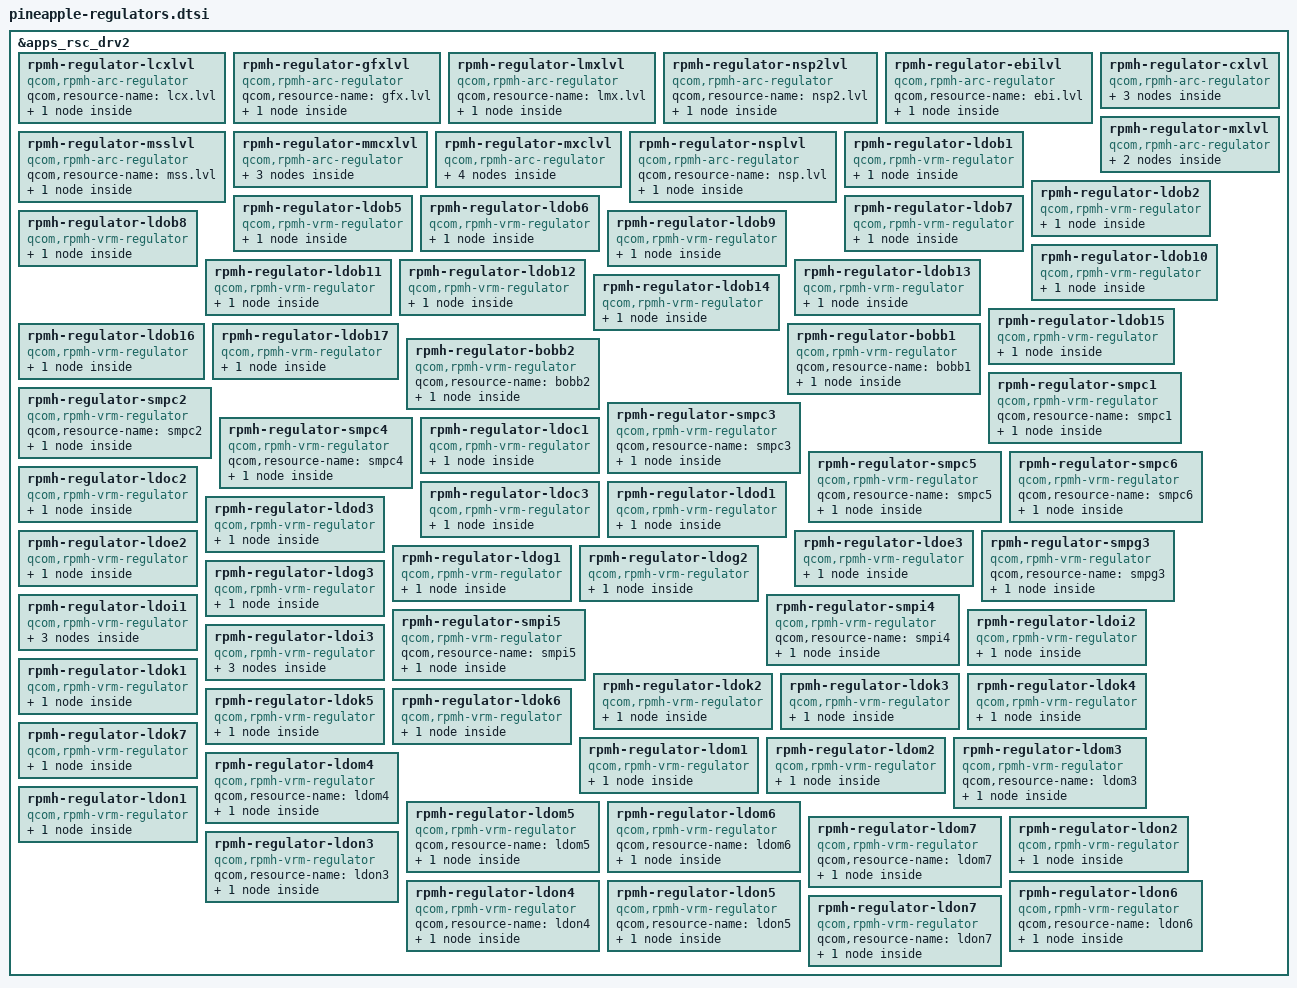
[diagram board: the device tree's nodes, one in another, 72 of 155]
// SPDX-License-Identifier: BSD-3-Clause
/*
 * Copyright (c) 2022-2023 Qualcomm Innovation Center, Inc. All rights reserved.
 */

#include <dt-bindings/regulator/qcom,rpmh-regulator-levels.h>

&apps_rsc_drv2 {
	rpmh-regulator-lcxlvl {
		compatible = "qcom,rpmh-arc-regulator";
		qcom,resource-name = "lcx.lvl";

		VDD_LPI_CX_LEVEL: S4D_LEVEL:
		pm_v6d_s4_level: regulator-pm-v6d-s4-level {
			regulator-name = "pm_v6d_s4_level";
			qcom,set = <RPMH_REGULATOR_SET_ALL>;
			regulator-min-microvolt =
				<RPMH_REGULATOR_LEVEL_RETENTION>;
			regulator-max-microvolt =
				<RPMH_REGULATOR_LEVEL_MAX>;
			qcom,init-voltage-level =
				<RPMH_REGULATOR_LEVEL_RETENTION>;
		};
	};

	rpmh-regulator-gfxlvl {
		compatible = "qcom,rpmh-arc-regulator";
		qcom,resource-name = "gfx.lvl";

		VDD_GFX_LEVEL: S5D_LEVEL:
		pm_v6d_s5_level: regulator-pm-v6d-s5-level {
			regulator-name = "pm_v6d_s5_level";
			qcom,set = <RPMH_REGULATOR_SET_ALL>;
			regulator-min-microvolt =
				<RPMH_REGULATOR_LEVEL_RETENTION>;
			regulator-max-microvolt =
				<RPMH_REGULATOR_LEVEL_MAX>;
			qcom,init-voltage-level =
				<RPMH_REGULATOR_LEVEL_RETENTION>;
		};
	};

	rpmh-regulator-lmxlvl {
		compatible = "qcom,rpmh-arc-regulator";
		qcom,resource-name = "lmx.lvl";

		VDD_LPI_MX_LEVEL: L2D_LEVEL:
		pm_v6d_l2_level: regulator-pm-v6d-l2-level {
			regulator-name = "pm_v6d_l2_level";
			qcom,set = <RPMH_REGULATOR_SET_ALL>;
			regulator-min-microvolt =
				<RPMH_REGULATOR_LEVEL_RETENTION>;
			regulator-max-microvolt =
				<RPMH_REGULATOR_LEVEL_MAX>;
			qcom,init-voltage-level =
				<RPMH_REGULATOR_LEVEL_RETENTION>;
		};
	};

	rpmh-regulator-nsp2lvl {
		compatible = "qcom,rpmh-arc-regulator";
		qcom,resource-name = "nsp2.lvl";

		VDD_NSP2_LEVEL: S1G_LEVEL:
		pm_v6g_s1_level: regulator-pm-v6g-s1-level {
			regulator-name = "pm_v6g_s1_level";
			qcom,set = <RPMH_REGULATOR_SET_ALL>;
			regulator-min-microvolt =
				<RPMH_REGULATOR_LEVEL_RETENTION>;
			regulator-max-microvolt =
				<RPMH_REGULATOR_LEVEL_MAX>;
			qcom,init-voltage-level =
				<RPMH_REGULATOR_LEVEL_RETENTION>;
		};
	};

	rpmh-regulator-ebilvl {
		compatible = "qcom,rpmh-arc-regulator";
		qcom,resource-name = "ebi.lvl";

		VDD_EBI_LEVEL: S4G_LEVEL:
		pm_v6g_s4_level: regulator-pm-v6g-s4-level {
			regulator-name = "pm_v6g_s4_level";
			qcom,set = <RPMH_REGULATOR_SET_ALL>;
			regulator-min-microvolt =
				<RPMH_REGULATOR_LEVEL_RETENTION>;
			regulator-max-microvolt =
				<RPMH_REGULATOR_LEVEL_MAX>;
			qcom,init-voltage-level =
				<RPMH_REGULATOR_LEVEL_RETENTION>;
		};
	};

	rpmh-regulator-msslvl {
		compatible = "qcom,rpmh-arc-regulator";
		qcom,resource-name = "mss.lvl";

		VDD_MODEM_LEVEL: S5G_LEVEL:
		pm_v6g_s5_level: regulator-pm-v6g-s5-level {
			regulator-name = "pm_v6g_s5_level";
			qcom,set = <RPMH_REGULATOR_SET_ALL>;
			regulator-min-microvolt =
				<RPMH_REGULATOR_LEVEL_RETENTION>;
			regulator-max-microvolt =
				<RPMH_REGULATOR_LEVEL_MAX>;
			qcom,init-voltage-level =
				<RPMH_REGULATOR_LEVEL_RETENTION>;
		};
	};

	rpmh-regulator-cxlvl {
		compatible = "qcom,rpmh-arc-regulator";
		qcom,resource-name = "cx.lvl";
		proxy-supply = <&VDD_CX_LEVEL>;

		VDD_CX_LEVEL: S8I_LEVEL:
		pm_v8_s8_level: regulator-pm-v8-s8-level {
			regulator-name = "pm_v8_s8_level";
			qcom,set = <RPMH_REGULATOR_SET_ALL>;
			regulator-min-microvolt =
				<RPMH_REGULATOR_LEVEL_RETENTION>;
			regulator-max-microvolt =
				<RPMH_REGULATOR_LEVEL_MAX>;
			qcom,init-voltage-level =
				<RPMH_REGULATOR_LEVEL_TURBO>;
			qcom,proxy-consumer-enable;
			qcom,proxy-consumer-voltage =
				<RPMH_REGULATOR_LEVEL_TURBO
				 RPMH_REGULATOR_LEVEL_MAX>;
		};

		VDD_CX_LEVEL_AO: S8I_LEVEL_AO:
		pm_v8_s8_level_ao: regulator-pm-v8-s8-level-ao {
			regulator-name = "pm_v8_s8_level_ao";
			qcom,set = <RPMH_REGULATOR_SET_ACTIVE>;
			regulator-min-microvolt =
				<RPMH_REGULATOR_LEVEL_RETENTION>;
			regulator-max-microvolt =
				<RPMH_REGULATOR_LEVEL_MAX>;
			qcom,init-voltage-level =
				<RPMH_REGULATOR_LEVEL_RETENTION>;
		};

		VDD_CX_MMCX_SUPPLY_LEVEL: regulator-pm-v8-s8-mmcx-sup-level {
			regulator-name = "pm_v8_s8_mmcx_sup_level";
			qcom,set = <RPMH_REGULATOR_SET_ALL>;
			regulator-min-microvolt =
				<RPMH_REGULATOR_LEVEL_MIN_SVS>;
			regulator-max-microvolt =
				<RPMH_REGULATOR_LEVEL_MAX>;
			qcom,init-voltage-level =
				<RPMH_REGULATOR_LEVEL_MIN_SVS>;
		};
	};

	rpmh-regulator-mmcxlvl {
		compatible = "qcom,rpmh-arc-regulator";
		qcom,resource-name = "mmcx.lvl";
		proxy-supply = <&VDD_MMCX_LEVEL>;

		VDD_MMCX_LEVEL: VDD_MM_LEVEL: S1I_LEVEL:
		pm_v8_s1_level: regulator-pm-v8-s1-level {
			regulator-name = "pm_v8_s1_level";
			qcom,set = <RPMH_REGULATOR_SET_ALL>;
			pm_v8_s1_level-parent-supply =
				<&VDD_CX_MMCX_SUPPLY_LEVEL>;
			regulator-min-microvolt =
				<RPMH_REGULATOR_LEVEL_LOW_SVS_D1>;
			regulator-max-microvolt =
				<RPMH_REGULATOR_LEVEL_MAX>;
			qcom,init-voltage-level =
				<RPMH_REGULATOR_LEVEL_TURBO>;
			qcom,proxy-consumer-enable;
			qcom,proxy-consumer-voltage =
				<RPMH_REGULATOR_LEVEL_TURBO
				 RPMH_REGULATOR_LEVEL_MAX>;
		};

		VDD_MMCX_LEVEL_AO: VDD_MM_LEVEL_AO: S1I_LEVEL_AO:
		pm_v8_s1_level_ao: regulator-pm-v8-s1-level-ao {
			regulator-name = "pm_v8_s1_level_ao";
			qcom,set = <RPMH_REGULATOR_SET_ACTIVE>;
			regulator-min-microvolt =
				<RPMH_REGULATOR_LEVEL_LOW_SVS_D1>;
			regulator-max-microvolt =
				<RPMH_REGULATOR_LEVEL_MAX>;
			qcom,init-voltage-level =
				<RPMH_REGULATOR_LEVEL_LOW_SVS_D1>;
		};

		regulator-pm-v8-s1-level-so {
			regulator-name = "pm_v8_s1_level_so";
			qcom,set = <RPMH_REGULATOR_SET_SLEEP>;
			regulator-min-microvolt =
				<RPMH_REGULATOR_LEVEL_LOW_SVS_D1>;
			regulator-max-microvolt =
				<RPMH_REGULATOR_LEVEL_MAX>;
			qcom,init-voltage-level =
				<RPMH_REGULATOR_LEVEL_LOW_SVS_D1>;
		};
	};

	rpmh-regulator-mxlvl {
		compatible = "qcom,rpmh-arc-regulator";
		qcom,resource-name = "mx.lvl";
		proxy-supply = <&VDD_MXA_LEVEL>;

		VDD_MXA_LEVEL: S3I_LEVEL:
		pm_v8_s3_level: regulator-pm-v8-s3-level {
			regulator-name = "pm_v8_s3_level";
			qcom,set = <RPMH_REGULATOR_SET_ALL>;
			regulator-min-microvolt =
				<RPMH_REGULATOR_LEVEL_RETENTION>;
			regulator-max-microvolt =
				<RPMH_REGULATOR_LEVEL_MAX>;
			qcom,init-voltage-level =
				<RPMH_REGULATOR_LEVEL_TURBO>;
			qcom,proxy-consumer-enable;
			qcom,proxy-consumer-voltage =
				<RPMH_REGULATOR_LEVEL_TURBO
				 RPMH_REGULATOR_LEVEL_MAX>;
		};

		VDD_MXA_LEVEL_AO: S3I_LEVEL_AO:
		pm_v8_s3_level_ao: regulator-pm-v8-s3-level-ao {
			regulator-name = "pm_v8_s3_level_ao";
			qcom,set = <RPMH_REGULATOR_SET_ACTIVE>;
			regulator-min-microvolt =
				<RPMH_REGULATOR_LEVEL_RETENTION>;
			regulator-max-microvolt =
				<RPMH_REGULATOR_LEVEL_MAX>;
			qcom,init-voltage-level =
				<RPMH_REGULATOR_LEVEL_RETENTION>;
		};
	};

	rpmh-regulator-mxclvl {
		compatible = "qcom,rpmh-arc-regulator";
		qcom,resource-name = "mxc.lvl";
		proxy-supply = <&VDD_MXC_LEVEL>;

		VDD_MXC_LEVEL: S3D_LEVEL:
		pm_v6d_s3_level: regulator-pm-v6d-s3-level {
			regulator-name = "pm_v6d_s3_level";
			qcom,set = <RPMH_REGULATOR_SET_ALL>;
			regulator-min-microvolt =
				<RPMH_REGULATOR_LEVEL_RETENTION>;
			regulator-max-microvolt =
				<RPMH_REGULATOR_LEVEL_MAX>;
			qcom,init-voltage-level =
				<RPMH_REGULATOR_LEVEL_TURBO>;
			qcom,proxy-consumer-enable;
			qcom,proxy-consumer-voltage =
				<RPMH_REGULATOR_LEVEL_TURBO
				 RPMH_REGULATOR_LEVEL_MAX>;
		};

		VDD_MXC_LEVEL_AO: S3D_LEVEL_AO:
		pm_v6d_s3_level_ao: regulator-pm-v6d-s3-level-ao {
			regulator-name = "pm_v6d_s3_level_ao";
			qcom,set = <RPMH_REGULATOR_SET_ACTIVE>;
			regulator-min-microvolt =
				<RPMH_REGULATOR_LEVEL_RETENTION>;
			regulator-max-microvolt =
				<RPMH_REGULATOR_LEVEL_MAX>;
			qcom,init-voltage-level =
				<RPMH_REGULATOR_LEVEL_RETENTION>;
		};

		VDD_MXC_MMCX_VOTER_LEVEL: VDD_MXC_MM_VOTER_LEVEL:
		VDD_MM_MXC_VOTER_LEVEL:
		regulator-pm-v6d-s3-mmcx-voter-level {
			regulator-name = "pm_v6d_s3_mmcx_voter_level";
			pm_v6d_s3_mmcx_voter_level-parent-supply =
				<&VDD_MMCX_LEVEL>;
			qcom,set = <RPMH_REGULATOR_SET_ALL>;
			regulator-min-microvolt =
				<RPMH_REGULATOR_LEVEL_MIN_SVS>;
			regulator-max-microvolt =
				<RPMH_REGULATOR_LEVEL_MAX>;
			qcom,init-voltage-level =
				<RPMH_REGULATOR_LEVEL_MIN_SVS>;
		};

		VDD_MXC_GFX_VOTER_LEVEL: VDD_GFX_MXC_VOTER_LEVEL:
		regulator-pm-v6d-s3-gfx-voter-level {
			regulator-name = "pm_v6d_s3_gfx_voter_level";
			pm_v6d_s3_gfx_voter_level-parent-supply =
				<&VDD_GFX_LEVEL>;
			qcom,set = <RPMH_REGULATOR_SET_ALL>;
			regulator-min-microvolt =
				<RPMH_REGULATOR_LEVEL_MIN_SVS>;
			regulator-max-microvolt =
				<RPMH_REGULATOR_LEVEL_MAX>;
			qcom,init-voltage-level =
				<RPMH_REGULATOR_LEVEL_MIN_SVS>;
		};
	};

	rpmh-regulator-nsplvl {
		compatible = "qcom,rpmh-arc-regulator";
		qcom,resource-name = "nsp.lvl";

		VDD_NSP1_LEVEL: S6I_LEVEL:
		pm_v8_s6_level: regulator-pm-v8-s6-level {
			regulator-name = "pm_v8_s6_level";
			qcom,set = <RPMH_REGULATOR_SET_ALL>;
			regulator-min-microvolt =
				<RPMH_REGULATOR_LEVEL_RETENTION>;
			regulator-max-microvolt =
				<RPMH_REGULATOR_LEVEL_MAX>;
			qcom,init-voltage-level =
				<RPMH_REGULATOR_LEVEL_RETENTION>;
		};
	};

	rpmh-regulator-ldob1 {
		compatible = "qcom,rpmh-vrm-regulator";
		qcom,resource-name = "ldob1";
		qcom,regulator-type = "pmic5-ldo";
		qcom,supported-modes =
			<RPMH_REGULATOR_MODE_LPM
			 RPMH_REGULATOR_MODE_HPM>;
		qcom,mode-threshold-currents = <0 30000>;

		L1B: pm_humu_l1: regulator-pm-humu-l1 {
			regulator-name = "pm_humu_l1";
			qcom,set = <RPMH_REGULATOR_SET_ALL>;
			regulator-min-microvolt = <1800000>;
			regulator-max-microvolt = <1800000>;
			qcom,init-voltage = <1800000>;
			qcom,init-mode = <RPMH_REGULATOR_MODE_HPM>;
		};
	};

	rpmh-regulator-ldob2 {
		compatible = "qcom,rpmh-vrm-regulator";
		qcom,resource-name = "ldob2";
		qcom,regulator-type = "pmic5-ldo";
		qcom,supported-modes =
			<RPMH_REGULATOR_MODE_LPM
			 RPMH_REGULATOR_MODE_HPM>;
		qcom,mode-threshold-currents = <0 10000>;

		L2B: pm_humu_l2: regulator-pm-humu-l2 {
			regulator-name = "pm_humu_l2";
			qcom,set = <RPMH_REGULATOR_SET_ALL>;
			regulator-min-microvolt = <3008000>;
			regulator-max-microvolt = <3008000>;
			qcom,init-voltage = <3008000>;
			qcom,init-mode = <RPMH_REGULATOR_MODE_HPM>;
		};
	};

	rpmh-regulator-ldob5 {
		compatible = "qcom,rpmh-vrm-regulator";
		qcom,resource-name = "ldob5";
		qcom,regulator-type = "pmic5-ldo";
		qcom,supported-modes =
			<RPMH_REGULATOR_MODE_LPM
			 RPMH_REGULATOR_MODE_HPM>;
		qcom,mode-threshold-currents = <0 10000>;

		L5B: pm_humu_l5: regulator-pm-humu-l5 {
			regulator-name = "pm_humu_l5";
			qcom,set = <RPMH_REGULATOR_SET_ALL>;
			regulator-min-microvolt = <3104000>;
			regulator-max-microvolt = <3104000>;
			qcom,init-voltage = <3104000>;
			qcom,init-mode = <RPMH_REGULATOR_MODE_HPM>;
		};
	};

	rpmh-regulator-ldob6 {
		compatible = "qcom,rpmh-vrm-regulator";
		qcom,resource-name = "ldob6";
		qcom,regulator-type = "pmic5-ldo";
		qcom,supported-modes =
			<RPMH_REGULATOR_MODE_LPM
			 RPMH_REGULATOR_MODE_HPM>;
		qcom,mode-threshold-currents = <0 10000>;

		L6B: pm_humu_l6: regulator-pm-humu-l6 {
			regulator-name = "pm_humu_l6";
			qcom,set = <RPMH_REGULATOR_SET_ALL>;
			regulator-min-microvolt = <1800000>;
			regulator-max-microvolt = <3008000>;
			qcom,init-voltage = <1800000>;
			qcom,init-mode = <RPMH_REGULATOR_MODE_HPM>;
		};
	};

	rpmh-regulator-ldob7 {
		compatible = "qcom,rpmh-vrm-regulator";
		qcom,resource-name = "ldob7";
		qcom,regulator-type = "pmic5-ldo";
		qcom,supported-modes =
			<RPMH_REGULATOR_MODE_LPM
			 RPMH_REGULATOR_MODE_HPM>;
		qcom,mode-threshold-currents = <0 10000>;

		L7B: pm_humu_l7: regulator-pm-humu-l7 {
			regulator-name = "pm_humu_l7";
			qcom,set = <RPMH_REGULATOR_SET_ALL>;
			regulator-min-microvolt = <1800000>;
			regulator-max-microvolt = <3008000>;
			qcom,init-voltage = <1800000>;
			qcom,init-mode = <RPMH_REGULATOR_MODE_HPM>;
		};
	};

	rpmh-regulator-ldob8 {
		compatible = "qcom,rpmh-vrm-regulator";
		qcom,resource-name = "ldob8";
		qcom,regulator-type = "pmic5-ldo";
		qcom,supported-modes =
			<RPMH_REGULATOR_MODE_LPM
			 RPMH_REGULATOR_MODE_HPM>;
		qcom,mode-threshold-currents = <0 10000>;

		L8B: pm_humu_l8: regulator-pm-humu-l8 {
			regulator-name = "pm_humu_l8";
			qcom,set = <RPMH_REGULATOR_SET_ALL>;
			regulator-min-microvolt = <1800000>;
			regulator-max-microvolt = <3008000>;
			qcom,init-voltage = <1800000>;
			qcom,init-mode = <RPMH_REGULATOR_MODE_HPM>;
		};
	};

	rpmh-regulator-ldob9 {
		compatible = "qcom,rpmh-vrm-regulator";
		qcom,resource-name = "ldob9";
		qcom,regulator-type = "pmic5-ldo";
		qcom,supported-modes =
			<RPMH_REGULATOR_MODE_LPM
			 RPMH_REGULATOR_MODE_HPM>;
		qcom,mode-threshold-currents = <0 10000>;

		L9B: pm_humu_l9: regulator-pm-humu-l9 {
			regulator-name = "pm_humu_l9";
			qcom,set = <RPMH_REGULATOR_SET_ALL>;
			regulator-min-microvolt = <2960000>;
			regulator-max-microvolt = <3008000>;
			qcom,init-voltage = <2960000>;
			qcom,init-mode = <RPMH_REGULATOR_MODE_HPM>;
		};
	};

	rpmh-regulator-ldob10 {
		compatible = "qcom,rpmh-vrm-regulator";
		qcom,resource-name = "ldob10";
		qcom,regulator-type = "pmic5-ldo";
		qcom,supported-modes =
			<RPMH_REGULATOR_MODE_LPM
			 RPMH_REGULATOR_MODE_HPM>;
		qcom,mode-threshold-currents = <0 30000>;

		L10B: pm_humu_l10: regulator-pm-humu-l10 {
			regulator-name = "pm_humu_l10";
			qcom,set = <RPMH_REGULATOR_SET_ALL>;
			regulator-min-microvolt = <1800000>;
			regulator-max-microvolt = <1800000>;
			qcom,init-voltage = <1800000>;
			qcom,init-mode = <RPMH_REGULATOR_MODE_HPM>;
		};
	};

	rpmh-regulator-ldob11 {
		compatible = "qcom,rpmh-vrm-regulator";
		qcom,resource-name = "ldob11";
		qcom,regulator-type = "pmic5-ldo";
		qcom,supported-modes =
			<RPMH_REGULATOR_MODE_LPM
			 RPMH_REGULATOR_MODE_HPM>;
		qcom,mode-threshold-currents = <0 30000>;
		proxy-supply = <&L11B>;

		L11B: pm_humu_l11: regulator-pm-humu-l11 {
			regulator-name = "pm_humu_l11";
			qcom,set = <RPMH_REGULATOR_SET_ALL>;
			regulator-min-microvolt = <1200000>;
			regulator-max-microvolt = <1200000>;
			qcom,init-voltage = <1200000>;
			qcom,init-mode = <RPMH_REGULATOR_MODE_HPM>;
			qcom,proxy-consumer-enable;
		};
	};

	rpmh-regulator-ldob12 {
		compatible = "qcom,rpmh-vrm-regulator";
		qcom,resource-name = "ldob12";
		qcom,regulator-type = "pmic5-ldo";
		qcom,supported-modes =
			<RPMH_REGULATOR_MODE_LPM
			 RPMH_REGULATOR_MODE_HPM>;
		qcom,mode-threshold-currents = <0 30000>;
		proxy-supply = <&L12B>;

		L12B: pm_humu_l12: regulator-pm-humu-l12 {
			regulator-name = "pm_humu_l12";
			qcom,set = <RPMH_REGULATOR_SET_ALL>;
			regulator-min-microvolt = <1800000>;
			regulator-max-microvolt = <1800000>;
			qcom,init-voltage = <1800000>;
			qcom,init-mode = <RPMH_REGULATOR_MODE_HPM>;
			qcom,proxy-consumer-enable;
		};
	};

	rpmh-regulator-ldob13 {
		compatible = "qcom,rpmh-vrm-regulator";
		qcom,resource-name = "ldob13";
		qcom,regulator-type = "pmic5-ldo";
		qcom,supported-modes =
			<RPMH_REGULATOR_MODE_LPM
			 RPMH_REGULATOR_MODE_HPM>;
		qcom,mode-threshold-currents = <0 10000>;
		proxy-supply = <&L13B>;

		L13B: pm_humu_l13: regulator-pm-humu-l13 {
			regulator-name = "pm_humu_l13";
			qcom,set = <RPMH_REGULATOR_SET_ALL>;
			regulator-min-microvolt = <3000000>;
			regulator-max-microvolt = <3000000>;
			qcom,init-voltage = <3000000>;
			qcom,init-mode = <RPMH_REGULATOR_MODE_HPM>;
			qcom,proxy-consumer-enable;
		};
	};

	rpmh-regulator-ldob14 {
		compatible = "qcom,rpmh-vrm-regulator";
		qcom,resource-name = "ldob14";
		qcom,regulator-type = "pmic5-ldo";
		qcom,supported-modes =
			<RPMH_REGULATOR_MODE_LPM
			 RPMH_REGULATOR_MODE_HPM>;
		qcom,mode-threshold-currents = <0 10000>;

		L14B: pm_humu_l14: regulator-pm-humu-l14 {
			regulator-name = "pm_humu_l14";
			qcom,set = <RPMH_REGULATOR_SET_ALL>;
			regulator-min-microvolt = <3200000>;
			regulator-max-microvolt = <3200000>;
			qcom,init-voltage = <3200000>;
			qcom,init-mode = <RPMH_REGULATOR_MODE_HPM>;
		};
	};

	rpmh-regulator-ldob15 {
		compatible = "qcom,rpmh-vrm-regulator";
		qcom,resource-name = "ldob15";
		qcom,regulator-type = "pmic5-ldo";
		qcom,supported-modes =
			<RPMH_REGULATOR_MODE_LPM
			 RPMH_REGULATOR_MODE_HPM>;
		qcom,mode-threshold-currents = <0 30000>;

		L15B: pm_humu_l15: regulator-pm-humu-l15 {
			regulator-name = "pm_humu_l15";
			qcom,set = <RPMH_REGULATOR_SET_ALL>;
			regulator-min-microvolt = <1800000>;
			regulator-max-microvolt = <1800000>;
			qcom,init-voltage = <1800000>;
			qcom,init-mode = <RPMH_REGULATOR_MODE_HPM>;
		};
	};

	rpmh-regulator-ldob16 {
		compatible = "qcom,rpmh-vrm-regulator";
		qcom,resource-name = "ldob16";
		qcom,regulator-type = "pmic5-ldo";
		qcom,supported-modes =
			<RPMH_REGULATOR_MODE_LPM
			 RPMH_REGULATOR_MODE_HPM>;
		qcom,mode-threshold-currents = <0 10000>;

		L16B: pm_humu_l16: regulator-pm-humu-l16 {
			regulator-name = "pm_humu_l16";
			qcom,set = <RPMH_REGULATOR_SET_ALL>;
			regulator-min-microvolt = <2800000>;
			regulator-max-microvolt = <2800000>;
			qcom,init-voltage = <2800000>;
			qcom,init-mode = <RPMH_REGULATOR_MODE_HPM>;
		};
	};

	rpmh-regulator-ldob17 {
		compatible = "qcom,rpmh-vrm-regulator";
		qcom,resource-name = "ldob17";
		qcom,regulator-type = "pmic5-ldo";
		qcom,supported-modes =
			<RPMH_REGULATOR_MODE_LPM
			 RPMH_REGULATOR_MODE_HPM>;
		qcom,mode-threshold-currents = <0 10000>;

		L17B: pm_humu_l17: regulator-pm-humu-l17 {
			regulator-name = "pm_humu_l17";
			qcom,set = <RPMH_REGULATOR_SET_ALL>;
			regulator-min-microvolt = <2504000>;
			regulator-max-microvolt = <2504000>;
			qcom,init-voltage = <2504000>;
			qcom,init-mode = <RPMH_REGULATOR_MODE_HPM>;
		};
	};

	rpmh-regulator-bobb1 {
		compatible = "qcom,rpmh-vrm-regulator";
		qcom,resource-name = "bobb1";

		BOB1: pm_humu_bob1: regulator-pm-humu-bob1 {
			regulator-name = "pm_humu_bob1";
			qcom,set = <RPMH_REGULATOR_SET_ALL>;
			regulator-min-microvolt = <3008000>;
			regulator-max-microvolt = <3960000>;
			qcom,init-voltage = <3296000>;
		};
	};

	rpmh-regulator-bobb2 {
		compatible = "qcom,rpmh-vrm-regulator";
		qcom,resource-name = "bobb2";

		BOB2: pm_humu_bob2: regulator-pm-humu-bob2 {
			regulator-name = "pm_humu_bob2";
			qcom,set = <RPMH_REGULATOR_SET_ALL>;
			regulator-min-microvolt = <2704000>;
			regulator-max-microvolt = <3008000>;
			qcom,init-voltage = <2720000>;
		};
	};

	rpmh-regulator-smpc1 {
		compatible = "qcom,rpmh-vrm-regulator";
		qcom,resource-name = "smpc1";

		S1C: pm_v6c_s1: regulator-pm-v6c-s1 {
			regulator-name = "pm_v6c_s1";
			qcom,set = <RPMH_REGULATOR_SET_ALL>;
			regulator-min-microvolt = <1224000>;
			regulator-max-microvolt = <1348000>;
			qcom,init-voltage = <1256000>;
		};
	};

	rpmh-regulator-smpc2 {
		compatible = "qcom,rpmh-vrm-regulator";
		qcom,resource-name = "smpc2";

		S2C: pm_v6c_s2: regulator-pm-v6c-s2 {
			regulator-name = "pm_v6c_s2";
			qcom,set = <RPMH_REGULATOR_SET_ALL>;
			regulator-min-microvolt = <500000>;
			regulator-max-microvolt = <1036000>;
			qcom,init-voltage = <852000>;
		};
	};

	rpmh-regulator-smpc3 {
		compatible = "qcom,rpmh-vrm-regulator";
		qcom,resource-name = "smpc3";

		S3C: pm_v6c_s3: regulator-pm-v6c-s3 {
			regulator-name = "pm_v6c_s3";
			qcom,set = <RPMH_REGULATOR_SET_ALL>;
			regulator-min-microvolt = <904000>;
			regulator-max-microvolt = <1064000>;
			qcom,init-voltage = <976000>;
		};
	};

	rpmh-regulator-smpc4 {
		compatible = "qcom,rpmh-vrm-regulator";
		qcom,resource-name = "smpc4";

		S4C: pm_v6c_s4: regulator-pm-v6c-s4 {
			regulator-name = "pm_v6c_s4";
			qcom,set = <RPMH_REGULATOR_SET_ALL>;
			regulator-min-microvolt = <1200000>;
			regulator-max-microvolt = <1280000>;
			qcom,init-voltage = <1224000>;
		};
	};

	rpmh-regulator-smpc5 {
		compatible = "qcom,rpmh-vrm-regulator";
		qcom,resource-name = "smpc5";

		S5C: pm_v6c_s5: regulator-pm-v6c-s5 {
			regulator-name = "pm_v6c_s5";
			qcom,set = <RPMH_REGULATOR_SET_ALL>;
			regulator-min-microvolt = <300000>;
			regulator-max-microvolt = <900000>;
			qcom,init-voltage = <752000>;
		};
	};

	rpmh-regulator-smpc6 {
		compatible = "qcom,rpmh-vrm-regulator";
		qcom,resource-name = "smpc6";

		S6C: pm_v6c_s6: regulator-pm-v6c-s6 {
			regulator-name = "pm_v6c_s6";
			qcom,set = <RPMH_REGULATOR_SET_ALL>;
			regulator-min-microvolt = <1856000>;
			regulator-max-microvolt = <2000000>;
			qcom,init-voltage = <1856000>;
		};
	};

	rpmh-regulator-ldoc1 {
		compatible = "qcom,rpmh-vrm-regulator";
		qcom,resource-name = "ldoc1";
		qcom,regulator-type = "pmic5-ldo";
		qcom,supported-modes =
			<RPMH_REGULATOR_MODE_LPM
			 RPMH_REGULATOR_MODE_HPM>;
		qcom,mode-threshold-currents = <0 30000>;

		L1C: pm_v6c_l1: regulator-pm-v6c-l1 {
			regulator-name = "pm_v6c_l1";
			qcom,set = <RPMH_REGULATOR_SET_ALL>;
			regulator-min-microvolt = <1100000>;
			regulator-max-microvolt = <1200000>;
			qcom,init-voltage = <1200000>;
			qcom,init-mode = <RPMH_REGULATOR_MODE_HPM>;
		};
	};

	rpmh-regulator-ldoc2 {
		compatible = "qcom,rpmh-vrm-regulator";
		qcom,resource-name = "ldoc2";
		qcom,regulator-type = "pmic5-ldo";
		qcom,supported-modes =
			<RPMH_REGULATOR_MODE_LPM
			 RPMH_REGULATOR_MODE_HPM>;
		qcom,mode-threshold-currents = <0 30000>;

		L2C: pm_v6c_l2: regulator-pm-v6c-l2 {
			regulator-name = "pm_v6c_l2";
			qcom,set = <RPMH_REGULATOR_SET_ALL>;
			regulator-min-microvolt = <1200000>;
			regulator-max-microvolt = <1200000>;
			qcom,init-voltage = <1200000>;
			qcom,init-mode = <RPMH_REGULATOR_MODE_HPM>;
		};
	};

	rpmh-regulator-ldoc3 {
		compatible = "qcom,rpmh-vrm-regulator";
		qcom,resource-name = "ldoc3";
		qcom,regulator-type = "pmic5-ldo";
		qcom,supported-modes =
			<RPMH_REGULATOR_MODE_LPM
			 RPMH_REGULATOR_MODE_HPM>;
		qcom,mode-threshold-currents = <0 30000>;

		L3C: pm_v6c_l3: regulator-pm-v6c-l3 {
			regulator-name = "pm_v6c_l3";
			qcom,set = <RPMH_REGULATOR_SET_ALL>;
			regulator-min-microvolt = <1200000>;
			regulator-max-microvolt = <1200000>;
			qcom,init-voltage = <1200000>;
			qcom,init-mode = <RPMH_REGULATOR_MODE_HPM>;
		};
	};

	rpmh-regulator-ldod1 {
		compatible = "qcom,rpmh-vrm-regulator";
		qcom,resource-name = "ldod1";
		qcom,regulator-type = "pmic5-ldo";
		qcom,supported-modes =
			<RPMH_REGULATOR_MODE_LPM
			 RPMH_REGULATOR_MODE_HPM>;
		qcom,mode-threshold-currents = <0 30000>;

		L1D: pm_v6d_l1: regulator-pm-v6d-l1 {
			regulator-name = "pm_v6d_l1";
			qcom,set = <RPMH_REGULATOR_SET_ALL>;
			regulator-min-microvolt = <880000>;
			regulator-max-microvolt = <920000>;
			qcom,init-voltage = <912000>;
			qcom,init-mode = <RPMH_REGULATOR_MODE_HPM>;
		};
	};

	rpmh-regulator-ldod3 {
		compatible = "qcom,rpmh-vrm-regulator";
		qcom,resource-name = "ldod3";
		qcom,regulator-type = "pmic5-ldo";
		qcom,supported-modes =
			<RPMH_REGULATOR_MODE_LPM
			 RPMH_REGULATOR_MODE_HPM>;
		qcom,mode-threshold-currents = <0 30000>;

		L3D: pm_v6d_l3: regulator-pm-v6d-l3 {
			regulator-name = "pm_v6d_l3";
			qcom,set = <RPMH_REGULATOR_SET_ALL>;
			regulator-min-microvolt = <800000>;
			regulator-max-microvolt = <900000>;
			qcom,init-voltage = <832000>;
			qcom,init-mode = <RPMH_REGULATOR_MODE_HPM>;
		};
	};

	rpmh-regulator-ldoe2 {
		compatible = "qcom,rpmh-vrm-regulator";
		qcom,resource-name = "ldoe2";
		qcom,regulator-type = "pmic5-ldo";
		qcom,supported-modes =
			<RPMH_REGULATOR_MODE_LPM
			 RPMH_REGULATOR_MODE_HPM>;
		qcom,mode-threshold-currents = <0 30000>;

		L2E: pm_v6e_l2: regulator-pm-v6e-l2 {
			regulator-name = "pm_v6e_l2";
			qcom,set = <RPMH_REGULATOR_SET_ALL>;
			regulator-min-microvolt = <864000>;
			regulator-max-microvolt = <972000>;
			qcom,init-voltage = <904000>;
			qcom,init-mode = <RPMH_REGULATOR_MODE_HPM>;
		};
	};

	rpmh-regulator-ldoe3 {
		compatible = "qcom,rpmh-vrm-regulator";
		qcom,resource-name = "ldoe3";
		qcom,regulator-type = "pmic5-ldo";
		qcom,supported-modes =
			<RPMH_REGULATOR_MODE_LPM
			 RPMH_REGULATOR_MODE_HPM>;
		qcom,mode-threshold-currents = <0 30000>;

		L3E: pm_v6e_l3: regulator-pm-v6e-l3 {
			regulator-name = "pm_v6e_l3";
			qcom,set = <RPMH_REGULATOR_SET_ALL>;
			regulator-min-microvolt = <880000>;
			regulator-max-microvolt = <920000>;
			qcom,init-voltage = <880000>;
			qcom,init-mode = <RPMH_REGULATOR_MODE_HPM>;
		};
	};

	rpmh-regulator-smpg3 {
		compatible = "qcom,rpmh-vrm-regulator";
		qcom,resource-name = "smpg3";

		S3G: pm_v6g_s3: regulator-pm-v6g-s3 {
			regulator-name = "pm_v6g_s3";
			qcom,set = <RPMH_REGULATOR_SET_ALL>;
			regulator-min-microvolt = <1000000>;
			regulator-max-microvolt = <1100000>;
			qcom,init-voltage = <1080000>;
		};
	};

	rpmh-regulator-ldog1 {
		compatible = "qcom,rpmh-vrm-regulator";
		qcom,resource-name = "ldog1";
		qcom,regulator-type = "pmic5-ldo";
		qcom,supported-modes =
			<RPMH_REGULATOR_MODE_LPM
			 RPMH_REGULATOR_MODE_HPM>;
		qcom,mode-threshold-currents = <0 30000>;

		L1G: pm_v6g_l1: regulator-pm-v6g-l1 {
			regulator-name = "pm_v6g_l1";
			qcom,set = <RPMH_REGULATOR_SET_ALL>;
			regulator-min-microvolt = <912000>;
			regulator-max-microvolt = <920000>;
			qcom,init-voltage = <912000>;
			qcom,init-mode = <RPMH_REGULATOR_MODE_HPM>;
		};
	};

	rpmh-regulator-ldog2 {
		compatible = "qcom,rpmh-vrm-regulator";
		qcom,resource-name = "ldog2";
		qcom,regulator-type = "pmic5-ldo";
		qcom,supported-modes =
			<RPMH_REGULATOR_MODE_LPM
			 RPMH_REGULATOR_MODE_HPM>;
		qcom,mode-threshold-currents = <0 30000>;

		L2G: pm_v6g_l2: regulator-pm-v6g-l2 {
			regulator-name = "pm_v6g_l2";
			qcom,set = <RPMH_REGULATOR_SET_ALL>;
			regulator-min-microvolt = <1200000>;
			regulator-max-microvolt = <1200000>;
			qcom,init-voltage = <1200000>;
			qcom,init-mode = <RPMH_REGULATOR_MODE_HPM>;
		};
	};

	rpmh-regulator-ldog3 {
		compatible = "qcom,rpmh-vrm-regulator";
		qcom,resource-name = "ldog3";
		qcom,regulator-type = "pmic5-ldo";
		qcom,supported-modes =
			<RPMH_REGULATOR_MODE_LPM
			 RPMH_REGULATOR_MODE_HPM>;
		qcom,mode-threshold-currents = <0 30000>;

		L3G: pm_v6g_l3: regulator-pm-v6g-l3 {
			regulator-name = "pm_v6g_l3";
			qcom,set = <RPMH_REGULATOR_SET_ALL>;
			regulator-min-microvolt = <880000>;
			regulator-max-microvolt = <912000>;
			qcom,init-voltage = <880000>;
			qcom,init-mode = <RPMH_REGULATOR_MODE_HPM>;
		};
	};

	rpmh-regulator-smpi4 {
		compatible = "qcom,rpmh-vrm-regulator";
		qcom,resource-name = "smpi4";

		S4I: pm_v8_s4: regulator-pm-v8-s4 {
			regulator-name = "pm_v8_s4";
			qcom,set = <RPMH_REGULATOR_SET_ALL>;
			regulator-min-microvolt = <300000>;
			regulator-max-microvolt = <1004000>;
			qcom,init-voltage = <852000>;
		};
	};

	rpmh-regulator-smpi5 {
		compatible = "qcom,rpmh-vrm-regulator";
		qcom,resource-name = "smpi5";

		S5I: pm_v8_s5: regulator-pm-v8-s5 {
			regulator-name = "pm_v8_s5";
			qcom,set = <RPMH_REGULATOR_SET_ALL>;
			regulator-min-microvolt = <300000>;
			regulator-max-microvolt = <700000>;
			qcom,init-voltage = <500000>;
		};
	};

	rpmh-regulator-ldoi1 {
		compatible = "qcom,rpmh-vrm-regulator";
		qcom,resource-name = "ldoi1";
		qcom,regulator-type = "pmic5-ldo";
		qcom,supported-modes =
			<RPMH_REGULATOR_MODE_LPM
			 RPMH_REGULATOR_MODE_HPM>;
		qcom,mode-threshold-currents = <0 30000>;
		proxy-supply = <&L1I>;

		L1I: pm_v8_l1: regulator-pm-v8-l1 {
			regulator-name = "pm_v8_l1";
			qcom,set = <RPMH_REGULATOR_SET_ALL>;
			regulator-min-microvolt = <880000>;
			regulator-max-microvolt = <912000>;
			qcom,init-voltage = <880000>;
			qcom,init-mode = <RPMH_REGULATOR_MODE_HPM>;
			qcom,proxy-consumer-enable;
		};

		L1I_AO: pm_v8_l1_ao: regulator-pm-v8-l1-ao {
			regulator-name = "pm_v8_l1_ao";
			qcom,set = <RPMH_REGULATOR_SET_ACTIVE>;
			regulator-min-microvolt = <880000>;
			regulator-max-microvolt = <912000>;
			qcom,init-voltage = <880000>;
			qcom,init-mode = <RPMH_REGULATOR_MODE_LPM>;
		};

		regulator-pm-v8-l1-so {
			regulator-name = "pm_v8_l1_so";
			qcom,set = <RPMH_REGULATOR_SET_SLEEP>;
			regulator-min-microvolt = <880000>;
			regulator-max-microvolt = <912000>;
			qcom,init-voltage = <880000>;
			qcom,init-mode = <RPMH_REGULATOR_MODE_LPM>;
			qcom,init-enable = <0>;
		};
	};

	rpmh-regulator-ldoi2 {
		compatible = "qcom,rpmh-vrm-regulator";
		qcom,resource-name = "ldoi2";
		qcom,regulator-type = "pmic5-ldo";
		qcom,supported-modes =
			<RPMH_REGULATOR_MODE_LPM
			 RPMH_REGULATOR_MODE_HPM>;
		qcom,mode-threshold-currents = <0 30000>;

		L2I: pm_v8_l2: regulator-pm-v8-l2 {
			regulator-name = "pm_v8_l2";
			qcom,set = <RPMH_REGULATOR_SET_ALL>;
			regulator-min-microvolt = <880000>;
			regulator-max-microvolt = <912000>;
			qcom,init-voltage = <880000>;
			qcom,init-mode = <RPMH_REGULATOR_MODE_HPM>;
		};
	};

	rpmh-regulator-ldoi3 {
		compatible = "qcom,rpmh-vrm-regulator";
		qcom,resource-name = "ldoi3";
		qcom,regulator-type = "pmic5-ldo";
		qcom,supported-modes =
			<RPMH_REGULATOR_MODE_LPM
			 RPMH_REGULATOR_MODE_HPM>;
		qcom,mode-threshold-currents = <0 30000>;
		proxy-supply = <&L3I>;

		L3I: pm_v8_l3: regulator-pm-v8-l3 {
			regulator-name = "pm_v8_l3";
			qcom,set = <RPMH_REGULATOR_SET_ALL>;
			regulator-min-microvolt = <1200000>;
			regulator-max-microvolt = <1200000>;
			qcom,init-voltage = <1200000>;
			qcom,init-mode = <RPMH_REGULATOR_MODE_HPM>;
			qcom,proxy-consumer-enable;
		};

		L3I_AO: pm_v8_l3_ao: regulator-pm-v8-l3-ao {
			regulator-name = "pm_v8_l3_ao";
			qcom,set = <RPMH_REGULATOR_SET_ACTIVE>;
			regulator-min-microvolt = <1200000>;
			regulator-max-microvolt = <1200000>;
			qcom,init-voltage = <1200000>;
			qcom,init-mode = <RPMH_REGULATOR_MODE_LPM>;
		};

		regulator-pm-v8-l3-so {
			regulator-name = "pm_v8_l3_so";
			qcom,set = <RPMH_REGULATOR_SET_SLEEP>;
			regulator-min-microvolt = <1200000>;
			regulator-max-microvolt = <1200000>;
			qcom,init-voltage = <1200000>;
			qcom,init-mode = <RPMH_REGULATOR_MODE_LPM>;
			qcom,init-enable = <0>;
		};
	};

	rpmh-regulator-ldok1 {
		compatible = "qcom,rpmh-vrm-regulator";
		qcom,resource-name = "ldok1";
		qcom,regulator-type = "pmic5-ldo";
		qcom,supported-modes =
			<RPMH_REGULATOR_MODE_LPM
			 RPMH_REGULATOR_MODE_HPM>;
		qcom,mode-threshold-currents = <0 30000>;

		L1K: pmr_nalojr_l1: regulator-pmr-nalojr-l1 {
			regulator-name = "pmr_nalojr_l1";
			qcom,set = <RPMH_REGULATOR_SET_ALL>;
			regulator-min-microvolt = <400000>;
			regulator-max-microvolt = <920000>;
			qcom,init-voltage = <856000>;
			qcom,init-mode = <RPMH_REGULATOR_MODE_HPM>;
		};
	};

	rpmh-regulator-ldok2 {
		compatible = "qcom,rpmh-vrm-regulator";
		qcom,resource-name = "ldok2";
		qcom,regulator-type = "pmic5-ldo";
		qcom,supported-modes =
			<RPMH_REGULATOR_MODE_LPM
			 RPMH_REGULATOR_MODE_HPM>;
		qcom,mode-threshold-currents = <0 30000>;

		L2K: pmr_nalojr_l2: regulator-pmr-nalojr-l2 {
			regulator-name = "pmr_nalojr_l2";
			qcom,set = <RPMH_REGULATOR_SET_ALL>;
			regulator-min-microvolt = <912000>;
			regulator-max-microvolt = <912000>;
			qcom,init-voltage = <912000>;
			qcom,init-mode = <RPMH_REGULATOR_MODE_HPM>;
		};
	};

	rpmh-regulator-ldok3 {
		compatible = "qcom,rpmh-vrm-regulator";
		qcom,resource-name = "ldok3";
		qcom,regulator-type = "pmic5-ldo";
		qcom,supported-modes =
			<RPMH_REGULATOR_MODE_LPM
			 RPMH_REGULATOR_MODE_HPM>;
		qcom,mode-threshold-currents = <0 30000>;

		L3K: pmr_nalojr_l3: regulator-pmr-nalojr-l3 {
			regulator-name = "pmr_nalojr_l3";
			qcom,set = <RPMH_REGULATOR_SET_ALL>;
			regulator-min-microvolt = <1200000>;
			regulator-max-microvolt = <1200000>;
			qcom,init-voltage = <1200000>;
			qcom,init-mode = <RPMH_REGULATOR_MODE_HPM>;
		};
	};

	rpmh-regulator-ldok4 {
		compatible = "qcom,rpmh-vrm-regulator";
		qcom,resource-name = "ldok4";
		qcom,regulator-type = "pmic5-ldo";
		qcom,supported-modes =
			<RPMH_REGULATOR_MODE_LPM
			 RPMH_REGULATOR_MODE_HPM>;
		qcom,mode-threshold-currents = <0 30000>;

		L4K: pmr_nalojr_l4: regulator-pmr-nalojr-l4 {
			regulator-name = "pmr_nalojr_l4";
			qcom,set = <RPMH_REGULATOR_SET_ALL>;
			regulator-min-microvolt = <1200000>;
			regulator-max-microvolt = <1200000>;
			qcom,init-voltage = <1200000>;
			qcom,init-mode = <RPMH_REGULATOR_MODE_HPM>;
		};
	};

	rpmh-regulator-ldok5 {
		compatible = "qcom,rpmh-vrm-regulator";
		qcom,resource-name = "ldok5";
		qcom,regulator-type = "pmic5-ldo";
		qcom,supported-modes =
			<RPMH_REGULATOR_MODE_LPM
			 RPMH_REGULATOR_MODE_HPM>;
		qcom,mode-threshold-currents = <0 30000>;

		L5K: pmr_nalojr_l5: regulator-pmr-nalojr-l5 {
			regulator-name = "pmr_nalojr_l5";
			qcom,set = <RPMH_REGULATOR_SET_ALL>;
			regulator-min-microvolt = <952000>;
			regulator-max-microvolt = <976000>;
			qcom,init-voltage = <952000>;
			qcom,init-mode = <RPMH_REGULATOR_MODE_HPM>;
		};
	};

	rpmh-regulator-ldok6 {
		compatible = "qcom,rpmh-vrm-regulator";
		qcom,resource-name = "ldok6";
		qcom,regulator-type = "pmic5-ldo";
		qcom,supported-modes =
			<RPMH_REGULATOR_MODE_LPM
			 RPMH_REGULATOR_MODE_HPM>;
		qcom,mode-threshold-currents = <0 30000>;

		L6K: pmr_nalojr_l6: regulator-pmr-nalojr-l6 {
			regulator-name = "pmr_nalojr_l6";
			qcom,set = <RPMH_REGULATOR_SET_ALL>;
			regulator-min-microvolt = <1776000>;
			regulator-max-microvolt = <1860000>;
			qcom,init-voltage = <1776000>;
			qcom,init-mode = <RPMH_REGULATOR_MODE_HPM>;
		};
	};

	rpmh-regulator-ldok7 {
		compatible = "qcom,rpmh-vrm-regulator";
		qcom,resource-name = "ldok7";
		qcom,regulator-type = "pmic5-ldo";
		qcom,supported-modes =
			<RPMH_REGULATOR_MODE_LPM
			 RPMH_REGULATOR_MODE_HPM>;
		qcom,mode-threshold-currents = <0 30000>;

		L7K: pmr_nalojr_l7: regulator-pmr-nalojr-l7 {
			regulator-name = "pmr_nalojr_l7";
			qcom,set = <RPMH_REGULATOR_SET_ALL>;
			regulator-min-microvolt = <800000>;
			regulator-max-microvolt = <800000>;
			qcom,init-voltage = <800000>;
			qcom,init-mode = <RPMH_REGULATOR_MODE_HPM>;
		};
	};

	rpmh-regulator-ldom1 {
		compatible = "qcom,rpmh-vrm-regulator";
		qcom,resource-name = "ldom1";
		qcom,regulator-type = "pmic5-ldo";
		qcom,supported-modes =
			<RPMH_REGULATOR_MODE_LPM
			 RPMH_REGULATOR_MODE_HPM>;
		qcom,mode-threshold-currents = <0 30000>;

		L1M: pm8010m_l1: regulator-pm8010m-l1 {
			regulator-name = "pm8010m_l1";
			qcom,set = <RPMH_REGULATOR_SET_ALL>;
			regulator-min-microvolt = <1104000>;
			regulator-max-microvolt = <1104000>;
			qcom,init-voltage = <1104000>;
			qcom,init-mode = <RPMH_REGULATOR_MODE_HPM>;
		};
	};

	rpmh-regulator-ldom2 {
		compatible = "qcom,rpmh-vrm-regulator";
		qcom,resource-name = "ldom2";
		qcom,regulator-type = "pmic5-ldo";
		qcom,supported-modes =
			<RPMH_REGULATOR_MODE_LPM
			 RPMH_REGULATOR_MODE_HPM>;
		qcom,mode-threshold-currents = <0 30000>;

		L2M: pm8010m_l2: regulator-pm8010m-l2 {
			regulator-name = "pm8010m_l2";
			qcom,set = <RPMH_REGULATOR_SET_ALL>;
			regulator-min-microvolt = <1056000>;
			regulator-max-microvolt = <1056000>;
			qcom,init-voltage = <1056000>;
			qcom,init-mode = <RPMH_REGULATOR_MODE_HPM>;
		};
	};

	rpmh-regulator-ldom3 {
		compatible = "qcom,rpmh-vrm-regulator";
		qcom,resource-name = "ldom3";

		L3M: pm8010m_l3: regulator-pm8010m-l3 {
			regulator-name = "pm8010m_l3";
			qcom,set = <RPMH_REGULATOR_SET_ALL>;
			regulator-min-microvolt = <2800000>;
			regulator-max-microvolt = <2800000>;
			qcom,init-voltage = <2800000>;
		};
	};

	rpmh-regulator-ldom4 {
		compatible = "qcom,rpmh-vrm-regulator";
		qcom,resource-name = "ldom4";

		L4M: pm8010m_l4: regulator-pm8010m-l4 {
			regulator-name = "pm8010m_l4";
			qcom,set = <RPMH_REGULATOR_SET_ALL>;
			regulator-min-microvolt = <2800000>;
			regulator-max-microvolt = <2800000>;
			qcom,init-voltage = <2800000>;
		};
	};

	rpmh-regulator-ldom5 {
		compatible = "qcom,rpmh-vrm-regulator";
		qcom,resource-name = "ldom5";

		L5M: pm8010m_l5: regulator-pm8010m-l5 {
			regulator-name = "pm8010m_l5";
			qcom,set = <RPMH_REGULATOR_SET_ALL>;
			regulator-min-microvolt = <1800000>;
			regulator-max-microvolt = <1800000>;
			qcom,init-voltage = <1800000>;
		};
	};

	rpmh-regulator-ldom6 {
		compatible = "qcom,rpmh-vrm-regulator";
		qcom,resource-name = "ldom6";

		L6M: pm8010m_l6: regulator-pm8010m-l6 {
			regulator-name = "pm8010m_l6";
			qcom,set = <RPMH_REGULATOR_SET_ALL>;
			regulator-min-microvolt = <2800000>;
			regulator-max-microvolt = <2800000>;
			qcom,init-voltage = <2800000>;
		};
	};

	rpmh-regulator-ldom7 {
		compatible = "qcom,rpmh-vrm-regulator";
		qcom,resource-name = "ldom7";

		L7M: pm8010m_l7: regulator-pm8010m-l7 {
			regulator-name = "pm8010m_l7";
			qcom,set = <RPMH_REGULATOR_SET_ALL>;
			regulator-min-microvolt = <2960000>;
			regulator-max-microvolt = <2960000>;
			qcom,init-voltage = <2960000>;
		};
	};

	rpmh-regulator-ldon1 {
		compatible = "qcom,rpmh-vrm-regulator";
		qcom,resource-name = "ldon1";
		qcom,regulator-type = "pmic5-ldo";
		qcom,supported-modes =
			<RPMH_REGULATOR_MODE_LPM
			 RPMH_REGULATOR_MODE_HPM>;
		qcom,mode-threshold-currents = <0 30000>;

		L1N: pm8010n_l1: regulator-pm8010n-l1 {
			regulator-name = "pm8010n_l1";
			qcom,set = <RPMH_REGULATOR_SET_ALL>;
			regulator-min-microvolt = <1104000>;
			regulator-max-microvolt = <1104000>;
			qcom,init-voltage = <1104000>;
			qcom,init-mode = <RPMH_REGULATOR_MODE_HPM>;
		};
	};

	rpmh-regulator-ldon2 {
		compatible = "qcom,rpmh-vrm-regulator";
		qcom,resource-name = "ldon2";
		qcom,regulator-type = "pmic5-ldo";
		qcom,supported-modes =
			<RPMH_REGULATOR_MODE_LPM
			 RPMH_REGULATOR_MODE_HPM>;
		qcom,mode-threshold-currents = <0 30000>;

		L2N: pm8010n_l2: regulator-pm8010n-l2 {
			regulator-name = "pm8010n_l2";
			qcom,set = <RPMH_REGULATOR_SET_ALL>;
			regulator-min-microvolt = <1056000>;
			regulator-max-microvolt = <1056000>;
			qcom,init-voltage = <1056000>;
			qcom,init-mode = <RPMH_REGULATOR_MODE_HPM>;
		};
	};

	rpmh-regulator-ldon3 {
		compatible = "qcom,rpmh-vrm-regulator";
		qcom,resource-name = "ldon3";

		L3N: pm8010n_l3: regulator-pm8010n-l3 {
			regulator-name = "pm8010n_l3";
			qcom,set = <RPMH_REGULATOR_SET_ALL>;
			regulator-min-microvolt = <1800000>;
			regulator-max-microvolt = <1800000>;
			qcom,init-voltage = <1800000>;
		};
	};

	rpmh-regulator-ldon4 {
		compatible = "qcom,rpmh-vrm-regulator";
		qcom,resource-name = "ldon4";

		L4N: pm8010n_l4: regulator-pm8010n-l4 {
			regulator-name = "pm8010n_l4";
			qcom,set = <RPMH_REGULATOR_SET_ALL>;
			regulator-min-microvolt = <1800000>;
			regulator-max-microvolt = <1800000>;
			qcom,init-voltage = <1800000>;
		};
	};

	rpmh-regulator-ldon5 {
		compatible = "qcom,rpmh-vrm-regulator";
		qcom,resource-name = "ldon5";

		L5N: pm8010n_l5: regulator-pm8010n-l5 {
			regulator-name = "pm8010n_l5";
			qcom,set = <RPMH_REGULATOR_SET_ALL>;
			regulator-min-microvolt = <2800000>;
			regulator-max-microvolt = <2800000>;
			qcom,init-voltage = <2800000>;
		};
	};

	rpmh-regulator-ldon6 {
		compatible = "qcom,rpmh-vrm-regulator";
		qcom,resource-name = "ldon6";

		L6N: pm8010n_l6: regulator-pm8010n-l6 {
			regulator-name = "pm8010n_l6";
			qcom,set = <RPMH_REGULATOR_SET_ALL>;
			regulator-min-microvolt = <2800000>;
			regulator-max-microvolt = <2800000>;
			qcom,init-voltage = <2800000>;
		};
	};

	rpmh-regulator-ldon7 {
		compatible = "qcom,rpmh-vrm-regulator";
		qcom,resource-name = "ldon7";

		L7N: pm8010n_l7: regulator-pm8010n-l7 {
			regulator-name = "pm8010n_l7";
			qcom,set = <RPMH_REGULATOR_SET_ALL>;
			regulator-min-microvolt = <3304000>;
			regulator-max-microvolt = <3304000>;
			qcom,init-voltage = <3304000>;
		};
	};
};
